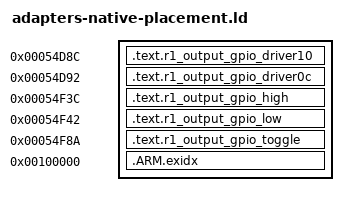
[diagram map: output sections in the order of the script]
SECTIONS {
.text.r1_output_gpio_driver10 0x54d8c : { *(.text.r1_output_gpio_driver10) }
.text.r1_output_gpio_driver0c 0x54d92 : { *(.text.r1_output_gpio_driver0c) }
.text.r1_output_gpio_high 0x54f3c : { *(.text.r1_output_gpio_high) }
.text.r1_output_gpio_low 0x54f42 : { *(.text.r1_output_gpio_low) }
.text.r1_output_gpio_toggle 0x54f8a : { *(.text.r1_output_gpio_toggle) }
 .ARM.exidx 0x100000 : { *(.ARM.exidx*) }
}
